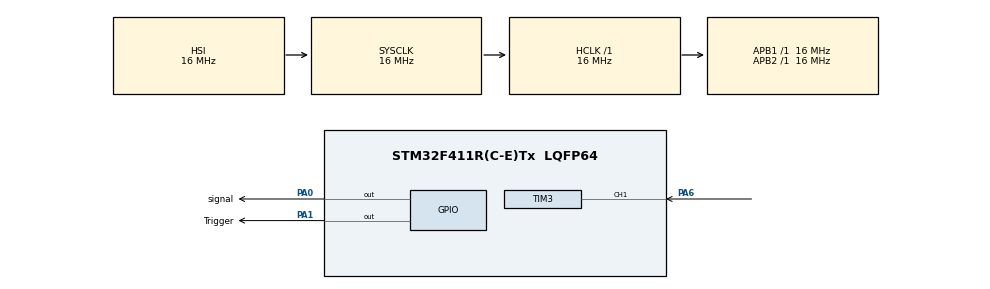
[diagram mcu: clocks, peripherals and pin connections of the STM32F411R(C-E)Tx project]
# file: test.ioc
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Mcu.Family=STM32F4
Mcu.Name=STM32F411R(C-E)Tx
Mcu.Package=LQFP64
NVIC.PriorityGroup=NVIC_PRIORITYGROUP_4
NVIC.TIM3_IRQn=true\:0\:0\:false\:false\:true\:true\:true\:true
PA0-WKUP.GPIO_Label=signal
PA0-WKUP.Signal=GPIO_Output
PA1.GPIO_Label=Trigger
PA1.Signal=GPIO_Output
PA6.Signal=S_TIM3_CH1
ProjectManager.HeapSize=0x200
ProjectManager.StackSize=0x400
ProjectManager.TargetToolchain=STM32CubeIDE
RCC.AHBFreq_Value=16000000
RCC.APB1Freq_Value=16000000
RCC.APB2Freq_Value=16000000
RCC.CortexFreq_Value=16000000
RCC.HSE_VALUE=25000000
RCC.HSI_VALUE=16000000
RCC.LSE_VALUE=32768
RCC.SYSCLKFreq_VALUE=16000000
RCC.VCOOutputFreq_Value=192000000
SH.S_TIM3_CH1.0=TIM3_CH1,Input_Capture1_from_TI1
TIM3.Channel-Input_Capture1_from_TI1=TIM_CHANNEL_1
TIM3.Period=0xFFFF-1
TIM3.Prescaler=15
VP_TIM3_VS_ClockSourceINT.Mode=Internal
board=custom

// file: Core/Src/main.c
/* USER CODE BEGIN Header */
/**
  ******************************************************************************
  * @file           : main.c
  * @brief          : Main program body
  ******************************************************************************
  * @attention
  *
  * Copyright (c) 2023 STMicroelectronics.
  * All rights reserved.
  *
  * This software is licensed under terms that can be found in the LICENSE file
  * in the root directory of this software component.
  * If no LICENSE file comes with this software, it is provided AS-IS.
  *
  ******************************************************************************
  */
/* USER CODE END Header */
#include "main.h"

TIM_HandleTypeDef htim3;

void SystemClock_Config(void);
static void MX_GPIO_Init(void);
static void MX_TIM3_Init(void);

/* USER CODE BEGIN 0 */
uint32_t IC_Val1=0;
uint32_t IC_Val2=0;
uint32_t Difference=0;
uint8_t IsFirstCaptured=0;
uint8_t Distance=0;

void delay_us(uint16_t time){
	__HAL_TIM_SET_COUNTER(&htim3,0);
	htim3.Instance->CNT=0;
	while(htim3.Instance->CNT<time);
}

HAL_TIM_IC_CaptureCallback(TIM_HandleTypeDef *htim)
{
	if(htim->Channel==HAL_TIM_ACTIVE_CHANNEL_1)
	{
		if(IsFirstCaptured==0)
		{
			IC_Val1=HAL_TIM_ReadCapturedValue(&htim3, TIM_CHANNEL_1);
			IsFirstCaptured=1;
		__HAL_TIM_SET_CAPTUREPOLARITY(htim,TIM_CHANNEL_1,TIM_INPUTCHANNELPOLARITY_FALLING); //interrupt direction change(rising>>falling)
		}
		else if(IsFirstCaptured==1)
		{
			IC_Val2=HAL_TIM_ReadCapturedValue(&htim3, TIM_CHANNEL_1);
			htim->Instance->CNT=0;
			if(IC_Val2>IC_Val1)
			{
				Difference=IC_Val2-IC_Val1;
			}
			else if(IC_Val2 < IC_Val1)
			{
				Difference=(0xffff-IC_Val1)+IC_Val2;
			}
			Distance=Difference*0.034/2;
			IsFirstCaptured=0;

			__HAL_TIM_SET_CAPTUREPOLARITY(htim,TIM_CHANNEL_1,TIM_INPUTCHANNELPOLARITY_RISING);
			__HAL_TIM_DISABLE_IT(htim,TIM_IT_CC1);
		}
	}
}

uint32_t getDistance(){
	HAL_GPIO_WritePin(Trigger_GPIO_Port, Trigger_Pin, 1);
	HAL_Delay(10);
	HAL_GPIO_WritePin(Trigger_GPIO_Port, Trigger_Pin, 0);

	__HAL_TIM_ENABLE_IT(&htim3,TIM_IT_CC1);
	return Distance;
}
/* USER CODE END 0 */

int main(void)
{

  /* MCU Configuration--------------------------------------------------------*/

  /* Reset of all peripherals, Initializes the Flash interface and the Systick. */
  HAL_Init();

  /* USER CODE BEGIN Init */
uint32_t distance=0;
  /* USER CODE END Init */

  /* Configure the system clock */
  SystemClock_Config();

  /* Initialize all configured peripherals */
  MX_GPIO_Init();
  MX_TIM3_Init();
  /* USER CODE BEGIN 2 */
  HAL_TIM_IC_Start_IT(&htim3, TIM_CHANNEL_1);
  /* USER CODE END 2 */

  /* Infinite loop */
  /* USER CODE BEGIN WHILE */
  while (1)
  {
  	distance=getDistance();
  	if(distance<=50)
  	{
  		HAL_GPIO_WritePin(signal_GPIO_Port, signal_Pin, 1);
  		HAL_Delay(1);
  	}
  	else
  	{
  		HAL_GPIO_WritePin(signal_GPIO_Port, signal_Pin, 0);
  		HAL_Delay(1);
  	}
    /* USER CODE END WHILE */

  }
}

void SystemClock_Config(void)
{
  RCC_OscInitTypeDef RCC_OscInitStruct = {0};
  RCC_ClkInitTypeDef RCC_ClkInitStruct = {0};

  /** Configure the main internal regulator output voltage
  */
  __HAL_RCC_PWR_CLK_ENABLE();
  __HAL_PWR_VOLTAGESCALING_CONFIG(PWR_REGULATOR_VOLTAGE_SCALE1);

  /** Initializes the RCC Oscillators according to the specified parameters
  * in the RCC_OscInitTypeDef structure.
  */
  RCC_OscInitStruct.OscillatorType = RCC_OSCILLATORTYPE_HSI;
  RCC_OscInitStruct.HSIState = RCC_HSI_ON;
  RCC_OscInitStruct.HSICalibrationValue = RCC_HSICALIBRATION_DEFAULT;
  RCC_OscInitStruct.PLL.PLLState = RCC_PLL_NONE;
  if (HAL_RCC_OscConfig(&RCC_OscInitStruct) != HAL_OK)
  {
    Error_Handler();
  }

  /** Initializes the CPU, AHB and APB buses clocks
  */
  RCC_ClkInitStruct.ClockType = RCC_CLOCKTYPE_HCLK|RCC_CLOCKTYPE_SYSCLK
                              |RCC_CLOCKTYPE_PCLK1|RCC_CLOCKTYPE_PCLK2;
  RCC_ClkInitStruct.SYSCLKSource = RCC_SYSCLKSOURCE_HSI;
  RCC_ClkInitStruct.AHBCLKDivider = RCC_SYSCLK_DIV1;
  RCC_ClkInitStruct.APB1CLKDivider = RCC_HCLK_DIV1;
  RCC_ClkInitStruct.APB2CLKDivider = RCC_HCLK_DIV1;

  if (HAL_RCC_ClockConfig(&RCC_ClkInitStruct, FLASH_LATENCY_0) != HAL_OK)
  {
    Error_Handler();
  }
}

static void MX_TIM3_Init(void)
{

  TIM_ClockConfigTypeDef sClockSourceConfig = {0};
  TIM_MasterConfigTypeDef sMasterConfig = {0};
  TIM_IC_InitTypeDef sConfigIC = {0};

  htim3.Instance = TIM3;
  htim3.Init.Prescaler = 15;
  htim3.Init.CounterMode = TIM_COUNTERMODE_UP;
  htim3.Init.Period = 0xFFFF-1;
  htim3.Init.ClockDivision = TIM_CLOCKDIVISION_DIV1;
  htim3.Init.AutoReloadPreload = TIM_AUTORELOAD_PRELOAD_DISABLE;
  if (HAL_TIM_Base_Init(&htim3) != HAL_OK)
  {
    Error_Handler();
  }
  sClockSourceConfig.ClockSource = TIM_CLOCKSOURCE_INTERNAL;
  if (HAL_TIM_ConfigClockSource(&htim3, &sClockSourceConfig) != HAL_OK)
  {
    Error_Handler();
  }
  if (HAL_TIM_IC_Init(&htim3) != HAL_OK)
  {
    Error_Handler();
  }
  sMasterConfig.MasterOutputTrigger = TIM_TRGO_RESET;
  sMasterConfig.MasterSlaveMode = TIM_MASTERSLAVEMODE_DISABLE;
  if (HAL_TIMEx_MasterConfigSynchronization(&htim3, &sMasterConfig) != HAL_OK)
  {
    Error_Handler();
  }
  sConfigIC.ICPolarity = TIM_INPUTCHANNELPOLARITY_RISING;
  sConfigIC.ICSelection = TIM_ICSELECTION_DIRECTTI;
  sConfigIC.ICPrescaler = TIM_ICPSC_DIV1;
  sConfigIC.ICFilter = 0;
  if (HAL_TIM_IC_ConfigChannel(&htim3, &sConfigIC, TIM_CHANNEL_1) != HAL_OK)
  {
    Error_Handler();
  }

}

static void MX_GPIO_Init(void)
{
  GPIO_InitTypeDef GPIO_InitStruct = {0};

  /* GPIO Ports Clock Enable */
  __HAL_RCC_GPIOA_CLK_ENABLE();

  /*Configure GPIO pin Output Level */
  HAL_GPIO_WritePin(GPIOA, signal_Pin|Trigger_Pin, GPIO_PIN_RESET);

  /*Configure GPIO pins : signal_Pin Trigger_Pin */
  GPIO_InitStruct.Pin = signal_Pin|Trigger_Pin;
  GPIO_InitStruct.Mode = GPIO_MODE_OUTPUT_PP;
  GPIO_InitStruct.Pull = GPIO_NOPULL;
  GPIO_InitStruct.Speed = GPIO_SPEED_FREQ_LOW;
  HAL_GPIO_Init(GPIOA, &GPIO_InitStruct);

}

void Error_Handler(void)
{
  __disable_irq();
  while (1)
  {
  }
}
